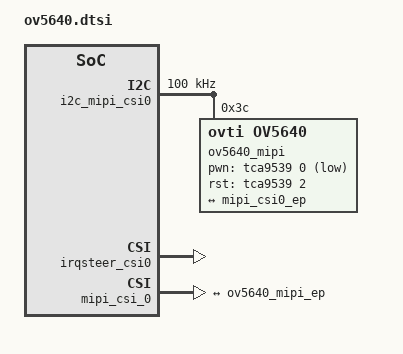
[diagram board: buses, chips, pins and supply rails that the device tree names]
/*
 * The code contained herein is licensed under the GNU General Public
 * License. You may obtain a copy of the GNU General Public License
 * Version 2 or later at the following locations:
 *
 * http://www.opensource.org/licenses/gpl-license.html
 * http://www.gnu.org/copyleft/gpl.html
 */

&i2c_mipi_csi0 {
	#address-cells = <1>;
	#size-cells = <0>;
	clock-frequency = <100000>;
	pinctrl-names = "default";
	pinctrl-0 = <&pinctrl_csi0_lpi2c0>;
	clkhi = <28>;
	clklo = <30>;
	status = "okay";

	ov5640_mipi: ov5640_mipi@3c {
		compatible = "ovti,ov5640";
		reg = <0x3c>;
		pinctrl-names = "default";
		pinctrl-0 = <&pinctrl_mipi_csi0>;
		clocks = <&xtal24m>;
		clock-names = "xclk";
		csi_id = <0>;
		pwn-gpios = <&tca9539 0 GPIO_ACTIVE_LOW>;
		rst-gpios = <&tca9539 2 GPIO_ACTIVE_HIGH>;
		mclk = <24000000>;
		mclk_source = <0>;
		mipi_csi;
		status = "okay";
		port {
			ov5640_mipi_ep: endpoint {
				remote-endpoint = <&mipi_csi0_ep>;
				data-lanes = <1 2>;
				clocks-lanes = <0>;
			};
		};
	};
};

&irqsteer_csi0 {
	status = "okay";
};

&mipi_csi_0 {
	#address-cells = <1>;
	#size-cells = <0>;
	status = "okay";

	port@0 {
		reg = <0>;
		mipi_csi0_ep: endpoint {
			remote-endpoint = <&ov5640_mipi_ep>;
			data-lanes = <1 2>;
		};
	};
};
